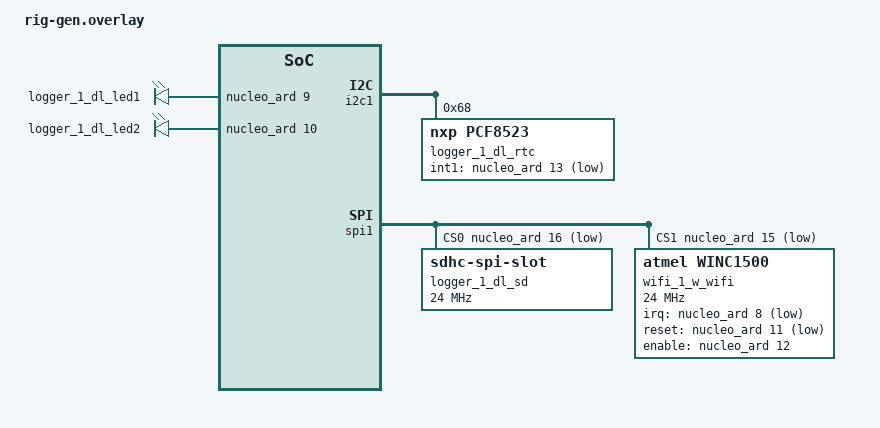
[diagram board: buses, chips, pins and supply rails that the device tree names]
/* generated by rigexp — do not edit; the rig file is the source of truth (R3)
 * rig: nucleo_wifi_logger_ok  board: nucleo_f401re/stm32f401xe/rig
 */

&i2c1 {
	logger_1_dl_rtc: rtc@68 {
		compatible = "nxp,pcf8523";
		alarms-count = <1>;
		battery-switch-over = "standard";
		reg = <0x68>;
		int1-gpios = <&nucleo_ard 13 0x11>;	/* D7 */
		status = "okay";
	};
};

&spi1 {
	cs-gpios = <&nucleo_ard 16 1 /* ACTIVE_LOW */>, <&nucleo_ard 15 1 /* ACTIVE_LOW */>;
	logger_1_dl_sd: sdhc@0 {
		compatible = "zephyr,sdhc-spi-slot";
		spi-max-frequency = <24000000>;
		reg = <0>;
		status = "okay";
		sdmmc {
			compatible = "zephyr,sdmmc-disk";
			disk-name = "SD";
			status = "okay";
		};
	};
	wifi_1_w_wifi: wifi@1 {
		compatible = "atmel,winc1500";
		spi-max-frequency = <24000000>;
		reg = <1>;
		irq-gpios = <&nucleo_ard 8 0x1>;	/* D2 */
		reset-gpios = <&nucleo_ard 11 0x1>;	/* D5 */
		enable-gpios = <&nucleo_ard 12 0x0>;	/* D6 */
		status = "okay";
	};
};

/ {
	gpio_leds: gpio_leds {
		compatible = "gpio-leds";
		logger_1_dl_led1: logger_1_dl_led1 {
			label = "logger_1_dl_led1";
			gpios = <&nucleo_ard 9 0x0>;	/* D3 */
		};
		logger_1_dl_led2: logger_1_dl_led2 {
			label = "logger_1_dl_led2";
			gpios = <&nucleo_ard 10 0x0>;	/* D4 */
		};
	};
};
